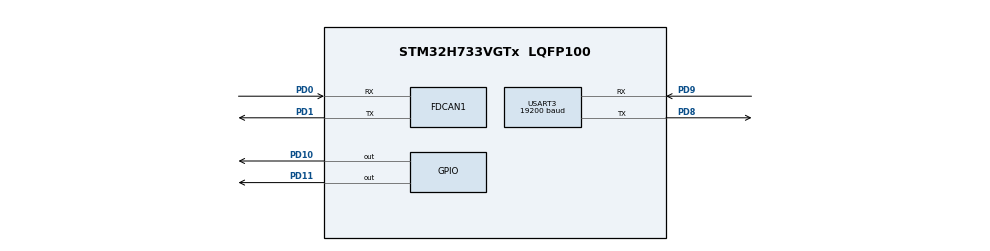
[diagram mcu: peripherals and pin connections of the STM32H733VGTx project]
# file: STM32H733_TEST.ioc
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Mcu.Family=STM32H7
NVIC.USART3_IRQn=true\:0\:0\:false\:false\:true\:true\:true
RCC.CortexFreq_Value=64000000
RCC.DIVQ1=4
RCC.PLLFRACN=0
PA13(JTMS/SWDIO).Signal=DEBUG_JTMS-SWDIO
PD9.GPIO_Speed=GPIO_SPEED_FREQ_VERY_HIGH
PD1.Signal=FDCAN1_TX
RCC.D2PPRE2=RCC_APB2_DIV2
RCC.D2PPRE1=RCC_APB1_DIV2
PD9.Signal=USART3_RX
PD9.Mode=Asynchronous
ProjectManager.StackSize=0x400
PA13(JTMS/SWDIO).Mode=Serial_Wire
USART3.VirtualMode-Asynchronous=VM_ASYNC
PD10.Signal=GPIO_Output
USART3.BaudRate=19200
ProjectManager.TargetToolchain=MDK-ARM V5
PD11.GPIO_Speed=GPIO_SPEED_FREQ_LOW
RCC.HCLKFreq_Value=64000000
RCC.DIVN1=12
PD0.Signal=FDCAN1_RX
PD8.Signal=USART3_TX
RCC.USBFreq_Value=48000000
PD8.Mode=Asynchronous
board=custom
RCC.DIVM1=4
PD1.Mode=FDCAN_Activate
RCC.APB2Freq_Value=32000000
VP_TIM2_VS_ClockSourceINT.Mode=Internal
FDCAN1.NominalPrescaler=6
NVIC.TIM2_IRQn=true\:0\:0\:false\:false\:true\:true\:true
RCC.ADCFreq_Value=129000000
TIM2.Period=104
PD10.GPIO_Speed=GPIO_SPEED_FREQ_VERY_HIGH
PA14(JTCK/SWCLK).Mode=Serial_Wire
Mcu.Name=STM32H733VGTx
PD0.Mode=FDCAN_Activate
FDCAN1.NominalTimeSeg2=7
FDCAN1.NominalTimeSeg1=6
RCC.APB3Freq_Value=32000000
RCC.SYSCLKFreq_VALUE=64000000
Mcu.Package=LQFP100
TIM2.Prescaler=64
RCC.D1PPRE=RCC_APB3_DIV2
PD11.Signal=GPIO_Output
ProjectManager.HeapSize=0x200
PD8.GPIO_Speed=GPIO_SPEED_FREQ_VERY_HIGH
NVIC.PriorityGroup=NVIC_PRIORITYGROUP_4
RCC.APB4Freq_Value=32000000
RCC.D3PPRE=RCC_APB4_DIV2
PA14(JTCK/SWCLK).Signal=DEBUG_JTCK-SWCLK
RCC.APB1Freq_Value=32000000
NVIC.FDCAN1_IT0_IRQn=true\:0\:0\:false\:false\:true\:true\:true

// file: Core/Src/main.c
/* USER CODE BEGIN Header */
/**
  ******************************************************************************
  * @file           : main.c
  * @brief          : Main program body
  ******************************************************************************
  * @attention
  *
  * <h2><center>&copy; Copyright (c) 2021 STMicroelectronics.
  * All rights reserved.</center></h2>
  *
  * This software component is licensed by ST under BSD 3-Clause license,
  * the "License"; You may not use this file except in compliance with the
  * License. You may obtain a copy of the License at:
  *                        opensource.org/licenses/BSD-3-Clause
  *
  ******************************************************************************
  */
/* USER CODE END Header */
#include "main.h"
#include "fdcan.h"
#include "tim.h"
#include "usart.h"
#include "gpio.h"

/* USER CODE BEGIN PV */
uint8_t RxBuffer[8] ;
uint8_t TxBuffer[8] = {0x55,0x55,0x55,0x55,0x00,0x00,0x00,0x00};
/* USER CODE END PV */

void SystemClock_Config(void);

int main(void)
{

  /* MCU Configuration--------------------------------------------------------*/

  /* Reset of all peripherals, Initializes the Flash interface and the Systick. */
  HAL_Init();

  /* Configure the system clock */
  SystemClock_Config();

  /* Initialize all configured peripherals */
  MX_GPIO_Init();
  MX_TIM2_Init();
  MX_USART3_UART_Init();
  MX_FDCAN1_Init();
  /* USER CODE BEGIN 2 */
	HAL_GPIO_WritePin(GPIOD, GPIO_PIN_11, GPIO_PIN_SET);  //使能引脚将CXPI变为Master模式
	HAL_TIM_Base_Start_IT(&htim2);
	HAL_UART_Receive_IT(&huart3, (uint8_t *)RxBuffer, 8);
  /* USER CODE END 2 */

  /* Infinite loop */
  while (1)
  {

    /* USER CODE BEGIN 3 */
		//HAL_Delay(200);
		HAL_UART_Transmit(&huart3, (uint8_t *)TxBuffer, 8,0xff);
  }
  /* USER CODE END 3 */
}

void SystemClock_Config(void)
{
  RCC_OscInitTypeDef RCC_OscInitStruct = {0};
  RCC_ClkInitTypeDef RCC_ClkInitStruct = {0};
  RCC_PeriphCLKInitTypeDef PeriphClkInitStruct = {0};

  /** Supply configuration update enable
  */
  HAL_PWREx_ConfigSupply(PWR_LDO_SUPPLY);
  /** Configure the main internal regulator output voltage
  */
  __HAL_PWR_VOLTAGESCALING_CONFIG(PWR_REGULATOR_VOLTAGE_SCALE3);

  while(!__HAL_PWR_GET_FLAG(PWR_FLAG_VOSRDY)) {}
  /** Initializes the RCC Oscillators according to the specified parameters
  * in the RCC_OscInitTypeDef structure.
  */
  RCC_OscInitStruct.OscillatorType = RCC_OSCILLATORTYPE_HSI;
  RCC_OscInitStruct.HSIState = RCC_HSI_DIV1;
  RCC_OscInitStruct.HSICalibrationValue = RCC_HSICALIBRATION_DEFAULT;
  RCC_OscInitStruct.PLL.PLLState = RCC_PLL_ON;
  RCC_OscInitStruct.PLL.PLLSource = RCC_PLLSOURCE_HSI;
  RCC_OscInitStruct.PLL.PLLM = 4;
  RCC_OscInitStruct.PLL.PLLN = 12;
  RCC_OscInitStruct.PLL.PLLP = 2;
  RCC_OscInitStruct.PLL.PLLQ = 4;
  RCC_OscInitStruct.PLL.PLLR = 2;
  RCC_OscInitStruct.PLL.PLLRGE = RCC_PLL1VCIRANGE_3;
  RCC_OscInitStruct.PLL.PLLVCOSEL = RCC_PLL1VCOWIDE;
  RCC_OscInitStruct.PLL.PLLFRACN = 0;
  if (HAL_RCC_OscConfig(&RCC_OscInitStruct) != HAL_OK)
  {
    Error_Handler();
  }
  /** Initializes the CPU, AHB and APB buses clocks
  */
  RCC_ClkInitStruct.ClockType = RCC_CLOCKTYPE_HCLK|RCC_CLOCKTYPE_SYSCLK
                              |RCC_CLOCKTYPE_PCLK1|RCC_CLOCKTYPE_PCLK2
                              |RCC_CLOCKTYPE_D3PCLK1|RCC_CLOCKTYPE_D1PCLK1;
  RCC_ClkInitStruct.SYSCLKSource = RCC_SYSCLKSOURCE_HSI;
  RCC_ClkInitStruct.SYSCLKDivider = RCC_SYSCLK_DIV1;
  RCC_ClkInitStruct.AHBCLKDivider = RCC_HCLK_DIV1;
  RCC_ClkInitStruct.APB3CLKDivider = RCC_APB3_DIV2;
  RCC_ClkInitStruct.APB1CLKDivider = RCC_APB1_DIV2;
  RCC_ClkInitStruct.APB2CLKDivider = RCC_APB2_DIV2;
  RCC_ClkInitStruct.APB4CLKDivider = RCC_APB4_DIV2;

  if (HAL_RCC_ClockConfig(&RCC_ClkInitStruct, FLASH_LATENCY_1) != HAL_OK)
  {
    Error_Handler();
  }
  PeriphClkInitStruct.PeriphClockSelection = RCC_PERIPHCLK_USART3|RCC_PERIPHCLK_FDCAN;
  PeriphClkInitStruct.FdcanClockSelection = RCC_FDCANCLKSOURCE_PLL;
  PeriphClkInitStruct.Usart234578ClockSelection = RCC_USART234578CLKSOURCE_D2PCLK1;
  if (HAL_RCCEx_PeriphCLKConfig(&PeriphClkInitStruct) != HAL_OK)
  {
    Error_Handler();
  }
}

void Error_Handler(void)
{
  __disable_irq();
  while (1)
  {
  }
}

/************************ (C) COPYRIGHT STMicroelectronics *****END OF FILE****/
